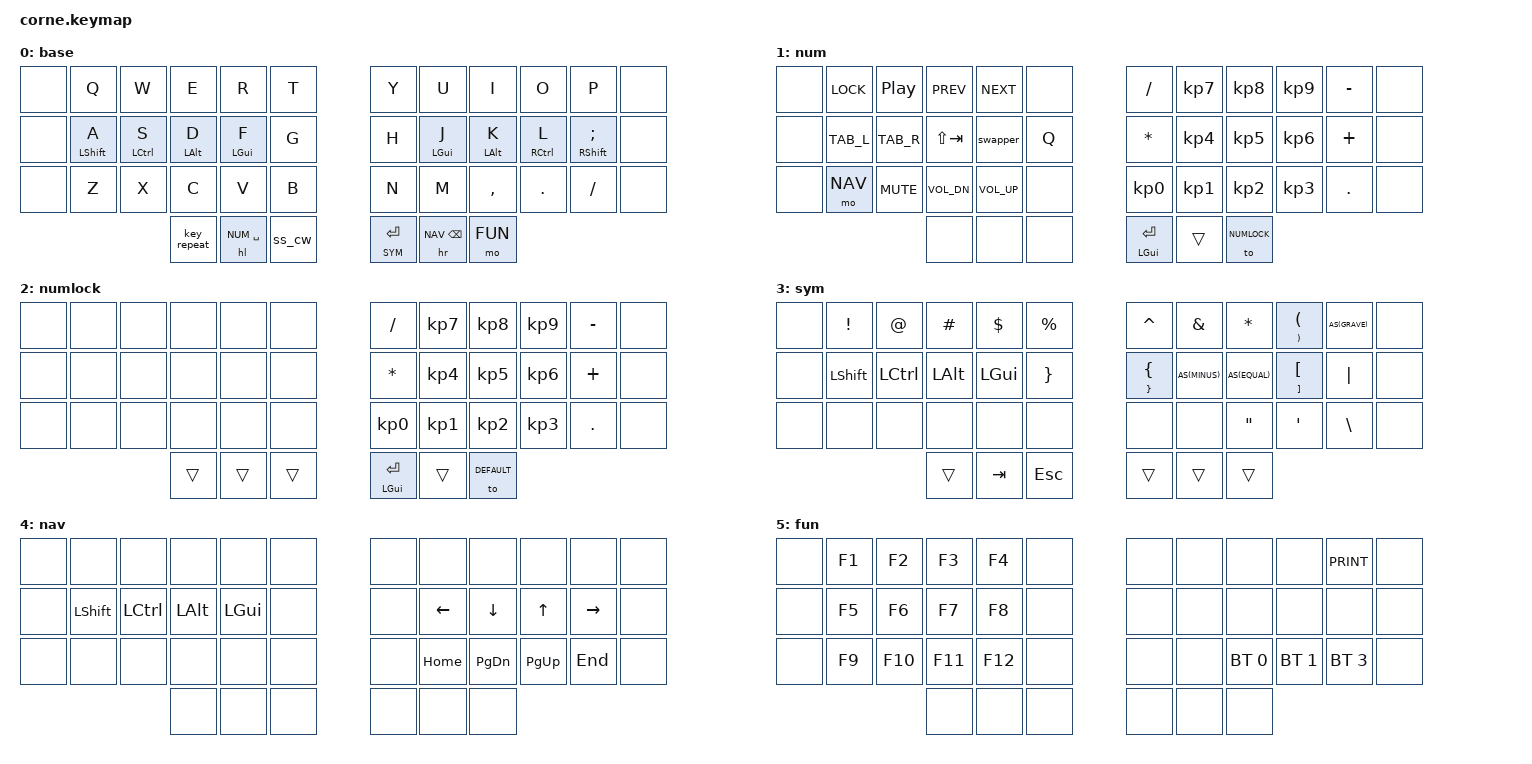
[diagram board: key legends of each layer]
// vim: filetype=c
/*
 * Copyright (c) 2020 The ZMK Contributors
 *
 * SPDX-License-Identifier: MIT
 */

#include <behaviors.dtsi>
#include <dt-bindings/zmk/keys.h>
#include <dt-bindings/zmk/bt.h>

/* use helper macros to define left and right hand keys */
#include "../zmk-nodefree-config/helper.h"

// The keyboard has 36 keys but the shields assume 42 
#include "../zmk-nodefree-config/keypos_def/keypos_42keys.h"

#define KEYS_L LT0 LT1 LT2 LT3 LT4 LT5 LM0 LM1 LM2 LM3 LM4 LM5 LB0 LB1 LB2 LB3 LB4 LB5 // left-hand keys
#define KEYS_R RT0 RT1 RT2 RT3 RT4 RT5 RM0 RM1 RM2 RM3 RM4 RM5 RB0 RB1 RB2 RB3 RB4 RB5 // right-hand keys
#define THUMBS LH2 LH1 LH0 RH0 RH1 RH2                                      // thumb keys

#define DEFAULT 0
#define NUM 1
#define NUMLOCK 2
#define SYM 3
#define NAV 4
#define FUN 5

#define PRINT LS(LG(N4))
#define LOCK LC(LG(Q))

// Firefox or tmux tabs
#define TAB_R LC(TAB)
#define TAB_L LS(LC(TAB))

#define xxx &none  
#define ___ &trans 

#define AS(keycode) &as LS(keycode) keycode     // Autoshift Macro

#define QUICK_TAP_MS 125
#define TAPPING_TERM_MS 275
#define PRIOR_IDLE_MS 150

// homerow mods
ZMK_BEHAVIOR(hml, hold_tap,
    flavor = "balanced";
    tapping-term-ms = <TAPPING_TERM_MS>;
    quick-tap-ms = <QUICK_TAP_MS>;
    require-prior-idle-ms = <PRIOR_IDLE_MS>;
    bindings = <&kp>, <&kp>;
    hold-trigger-key-positions = <KEYS_R THUMBS>;
    hold-trigger-on-release;             // delay positional check until key-release
)

ZMK_BEHAVIOR(hmr, hold_tap,
    flavor = "balanced";
    tapping-term-ms = <TAPPING_TERM_MS>;
    quick-tap-ms = <QUICK_TAP_MS>;
    require-prior-idle-ms = <PRIOR_IDLE_MS>;
    bindings = <&kp>, <&kp>;
    hold-trigger-key-positions = <KEYS_L THUMBS>;
    hold-trigger-on-release;             // delay positional check until key-release
)

ZMK_BEHAVIOR(ss_cw, tap_dance,
    tapping-term-ms = <200>;
    bindings = <&sk LSHFT>, <&caps_word>;
)

// Cmd+Tab swapper
ZMK_BEHAVIOR(swapper, tri_state,
    bindings = <&kt LGUI>, <&kp TAB>, <&kt LGUI>;
    ignored-key-positions = <LM0 LM2>;
)

// Left-hand hold, used for Num layer
ZMK_BEHAVIOR(hl, hold_tap,
    flavor = "balanced";
    tapping-term-ms = <275>;
    quick-tap-ms = <QUICK_TAP_MS>;
    require-prior-idle-ms = <100>;
    bindings = <&mo>, <&kp>;
    hold-trigger-key-positions = <KEYS_R THUMBS>;
    hold-trigger-on-release;
)

// Right hand hold, used for Nav layer
ZMK_BEHAVIOR(hr, hold_tap,
    flavor = "tap-preferred";
    tapping-term-ms = <175>;
    quick-tap-ms = <QUICK_TAP_MS>;
    bindings = <&mo>, <&kp>;
)

ZMK_BEHAVIOR(as, hold_tap,
    flavor = "tap-preferred";
    bindings = <&kp>, <&kp>;
    tapping-term-ms = <175>;
    quick-tap-ms = <0>;
)

&sk {  // sticky-key config
    release-after-ms = <900>;  // release after 0.6s
    quick-release;             // no double capitalization when rolling keys
};

// Long term hold, used for Sym layer
&lt {
    flavor = "hold-preferred";
    tapping-term-ms = <125>;
    quick-tap-ms = <QUICK_TAP_MS>;
};

ZMK_COMBO(esc,  &kp ESC, LT3 LT4, ALL, 25)

// Clear bluetooth by pressing y and u on the FUN layer
ZMK_COMBO(bt_clr, &bt BT_CLR, RT0 RT1, FUN, 25)

ZMK_LAYER(base,
     // ╭─────────────┬─────────────┬─────────────┬─────────────┬─────────────╮   ╭─────────────┬─────────────┬─────────────┬─────────────┬─────────────╮
  xxx     &kp Q         &kp W         &kp E         &kp R         &kp T             &kp Y         &kp U         &kp I         &kp O         &kp P           xxx
     // ├─────────────┼─────────────┼─────────────┼─────────────┼─────────────┤   ├─────────────┼─────────────┼─────────────┼─────────────┼─────────────┤
  xxx     &hml LSHFT A  &hml LCTL S   &hml LALT D   &hml LGUI F   &kp G             &kp H         &hmr LGUI J   &hmr LALT K   &hmr RCTL L   &hmr RSHFT SEMI xxx
     // ├─────────────┼─────────────┼─────────────┼─────────────┼─────────────┤   ├─────────────┼─────────────┼─────────────┼─────────────┼─────────────┤
  xxx     &kp Z         &kp X         &kp C         &kp V         &kp B             &kp N         &kp M         &kp COMMA     &kp DOT       &kp FSLH        xxx
     // ╰─────────────┼─────────────┼─────────────┼─────────────┼─────────────┤   ├─────────────┼─────────────┼─────────────┼─────────────┼─────────────┤
                                      &key_repeat   &hl NUM SPACE &ss_cw            &lt SYM RET   &hr NAV BSPC  &mo FUN
     //                             ╰─────────────┴─────────────┴─────────────╯   ╰─────────────┴─────────────┴─────────────╯
)

ZMK_LAYER(num,
     // ╭─────────────┬─────────────┬─────────────┬─────────────┬─────────────╮   ╭─────────────┬─────────────┬─────────────┬─────────────┬─────────────╮
  xxx     &kp LOCK      &kp C_PP      &kp C_PREV    &kp C_NEXT    xxx               &kp SLASH     &kp KP_N7     &kp KP_N8     &kp KP_N9     &kp MINUS       xxx
     // ├─────────────┼─────────────┼─────────────┼─────────────┼─────────────┤   ├─────────────┼─────────────┼─────────────┼─────────────┼─────────────┤
  xxx     &kp TAB_L     &kp TAB_R     &kp LS(TAB)   &swapper      &kp Q             &kp ASTRK     &kp KP_N4     &kp KP_N5     &kp KP_N6     &kp PLUS        xxx
     // ├─────────────┼─────────────┼─────────────┼─────────────┼─────────────┤   ├─────────────┼─────────────┼─────────────┼─────────────┼─────────────┤
  xxx     &mo NAV       &kp C_MUTE    &kp C_VOL_DN  &kp C_VOL_UP  xxx               &kp KP_N0     &kp KP_N1     &kp KP_N2     &kp KP_N3     &kp DOT         xxx
     // ╰─────────────┼─────────────┼─────────────┼─────────────┼─────────────┤   ├─────────────┼─────────────┼─────────────┼─────────────┼─────────────┤
                                      xxx           xxx           xxx               &mt LGUI RET  ___           &to NUMLOCK   
     //                             ╰─────────────┴─────────────┴─────────────╯   ╰─────────────┴─────────────┴─────────────╯
)

// TODO: there doesn't seem to be a good way to avoid this duplication
ZMK_LAYER(numlock,
     // ╭─────────────┬─────────────┬─────────────┬─────────────┬─────────────╮   ╭─────────────┬─────────────┬─────────────┬─────────────┬─────────────╮
  xxx     xxx           xxx           xxx           xxx           xxx               &kp SLASH     &kp KP_N7     &kp KP_N8     &kp KP_N9     &kp MINUS       xxx
     // ├─────────────┼─────────────┼─────────────┼─────────────┼─────────────┤   ├─────────────┼─────────────┼─────────────┼─────────────┼─────────────┤
  xxx     xxx           xxx           xxx           xxx           xxx               &kp ASTRK     &kp KP_N4     &kp KP_N5     &kp KP_N6     &kp PLUS        xxx
     // ├─────────────┼─────────────┼─────────────┼─────────────┼─────────────┤   ├─────────────┼─────────────┼─────────────┼─────────────┼─────────────┤
  xxx     xxx           xxx           xxx           xxx           xxx               &kp KP_N0     &kp KP_N1     &kp KP_N2     &kp KP_N3     &kp DOT         xxx
     // ╰─────────────┼─────────────┼─────────────┼─────────────┼─────────────┤   ├─────────────┼─────────────┼─────────────┼─────────────┼─────────────┤
                                      ___           ___           ___               &mt LGUI RET  ___           &to DEFAULT   
     //                             ╰─────────────┴─────────────┴─────────────╯   ╰─────────────┴─────────────┴─────────────╯
)


ZMK_LAYER(sym,
     // ╭─────────────┬─────────────┬─────────────┬─────────────┬─────────────╮   ╭─────────────┬─────────────┬─────────────┬─────────────┬─────────────╮
  xxx     &kp EXCL      &kp AT        &kp HASH      &kp DLLR      &kp PRCNT         &kp CARET     &kp AMPS      &kp ASTRK     &as RPAR LPAR AS(GRAVE)       xxx
     // ├─────────────┼─────────────┼─────────────┼─────────────┼─────────────┤   ├─────────────┼─────────────┼─────────────┼─────────────┼─────────────┤
  xxx     &kp LSHFT     &kp LCTL      &kp LALT      &kp LGUI      &kp RBRC          &as RBRC LBRC AS(MINUS)     AS(EQUAL)     &as RBKT LBKT &kp PIPE        xxx
     // ├─────────────┼─────────────┼─────────────┼─────────────┼─────────────┤   ├─────────────┼─────────────┼─────────────┼─────────────┼─────────────┤
  xxx     xxx           xxx           xxx           xxx           xxx               xxx           xxx           &kp DQT       &kp SQT       &kp BSLH        xxx
     // ╰─────────────┼─────────────┼─────────────┼─────────────┼─────────────┤   ├─────────────┼─────────────┼─────────────┼─────────────┼─────────────┤
                                      ___           &kp TAB       &kp ESC           ___           ___           ___   
     //                             ╰─────────────┴─────────────┴─────────────╯   ╰─────────────┴─────────────┴─────────────╯
)

ZMK_LAYER(nav,
     // ╭─────────────┬─────────────┬─────────────┬─────────────┬─────────────╮   ╭─────────────┬─────────────┬─────────────┬─────────────┬─────────────╮
  xxx     xxx           xxx           xxx           xxx           xxx               xxx           xxx           xxx           xxx           xxx             xxx
     // ├─────────────┼─────────────┼─────────────┼─────────────┼─────────────┤   ├─────────────┼─────────────┼─────────────┼─────────────┼─────────────┤
  xxx     &kp LSHFT     &kp LCTL      &kp LALT      &kp LGUI      xxx               xxx           &kp LEFT      &kp DOWN      &kp UP        &kp RIGHT       xxx
     // ├─────────────┼─────────────┼─────────────┼─────────────┼─────────────┤   ├─────────────┼─────────────┼─────────────┼─────────────┼─────────────┤
  xxx     xxx           xxx           xxx           xxx           xxx               xxx           &kp HOME      &kp PG_DN     &kp PG_UP     &kp END         xxx
     // ╰─────────────┼─────────────┼─────────────┼─────────────┼─────────────┤   ├─────────────┼─────────────┼─────────────┼─────────────┼─────────────┤
                                      xxx           xxx           xxx               xxx           xxx           xxx         
     //                             ╰─────────────┴─────────────┴─────────────╯   ╰─────────────┴─────────────┴─────────────╯
)

ZMK_LAYER(fun,
     // ╭─────────────┬─────────────┬─────────────┬─────────────┬─────────────╮   ╭─────────────┬─────────────┬─────────────┬─────────────┬─────────────╮
  xxx     &kp F1        &kp F2        &kp F3        &kp F4        xxx               xxx           xxx           xxx           xxx           &kp PRINT      xxx
     // ├─────────────┼─────────────┼─────────────┼─────────────┼─────────────┤   ├─────────────┼─────────────┼─────────────┼─────────────┼─────────────┤
  xxx     &kp F5        &kp F6        &kp F7        &kp F8        xxx               xxx           xxx           xxx           xxx           xxx            xxx
     // ├─────────────┼─────────────┼─────────────┼─────────────┼─────────────┤   ├─────────────┼─────────────┼─────────────┼─────────────┼─────────────┤
  xxx     &kp F9        &kp F10       &kp F11       &kp F12       xxx               xxx           xxx           &bt BT_SEL 0  &bt BT_SEL 1  &bt BT_SEL 3   xxx
     // ╰─────────────┼─────────────┼─────────────┼─────────────┼─────────────┤   ├─────────────┼─────────────┼─────────────┼─────────────┼─────────────┤
                                      xxx           xxx           xxx               xxx           xxx           xxx  
     //                             ╰─────────────┴─────────────┴─────────────╯   ╰─────────────┴─────────────┴─────────────╯
)
